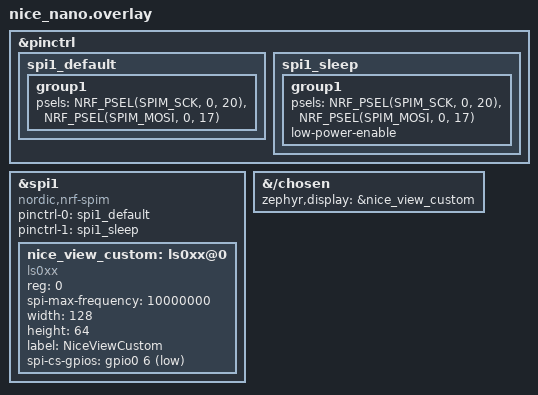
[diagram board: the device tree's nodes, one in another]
&pinctrl {
    spi1_default: spi1_default {
        group1 {
            psels = <NRF_PSEL(SPIM_SCK, 0, 20)>,     /* SCK */
                    <NRF_PSEL(SPIM_MOSI, 0, 17)>;    /* MOSI */
        };
    };

    spi1_sleep: spi1_sleep {
        group1 {
            psels = <NRF_PSEL(SPIM_SCK, 0, 20)>,
                    <NRF_PSEL(SPIM_MOSI, 0, 17)>;
            low-power-enable;
        };
    };
};

&spi1 {
    compatible = "nordic,nrf-spim";
    status = "okay";

    pinctrl-0 = <&spi1_default>;
    pinctrl-1 = <&spi1_sleep>;
    pinctrl-names = "default", "sleep";

    nice_view_custom: ls0xx@0 {
        compatible = "ls0xx";
        reg = <0>;
        spi-max-frequency = <10000000>;
        width = <128>;
        height = <64>;
        label = "NiceViewCustom";
        spi-cs-gpios = <&gpio0 6 GPIO_ACTIVE_LOW>;
    };
};

&{/chosen} {
    zephyr,display = &nice_view_custom;
};
